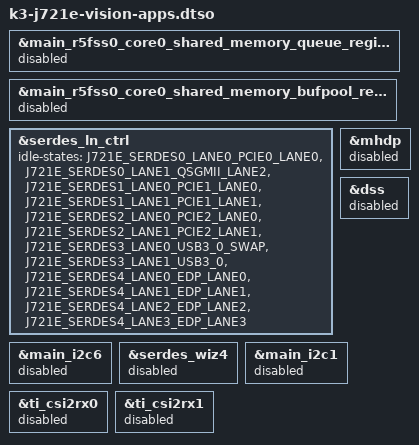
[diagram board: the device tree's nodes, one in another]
// SPDX-License-Identifier: GPL-2.0
/*
 * vision-apps: device-tree overlay
 *
 * Copyright (C) 2019 - 2021 Texas Instruments Incorporated - http://www.ti.com/
 */

/dts-v1/;
/plugin/;

#include <dt-bindings/mux/ti-serdes.h>

&main_r5fss0_core0_shared_memory_queue_region {
	status = "disabled";
};

&main_r5fss0_core0_shared_memory_bufpool_region {
	status = "disabled";
};

&serdes_ln_ctrl {
	idle-states = <J721E_SERDES0_LANE0_PCIE0_LANE0>, <J721E_SERDES0_LANE1_QSGMII_LANE2>,
		      <J721E_SERDES1_LANE0_PCIE1_LANE0>, <J721E_SERDES1_LANE1_PCIE1_LANE1>,
		      <J721E_SERDES2_LANE0_PCIE2_LANE0>, <J721E_SERDES2_LANE1_PCIE2_LANE1>,
		      <J721E_SERDES3_LANE0_USB3_0_SWAP>, <J721E_SERDES3_LANE1_USB3_0>,
		      <J721E_SERDES4_LANE0_EDP_LANE0>, <J721E_SERDES4_LANE1_EDP_LANE1>,
		      <J721E_SERDES4_LANE2_EDP_LANE2>, <J721E_SERDES4_LANE3_EDP_LANE3>;
};

#include "k3-j721e-rtos-memory-map.dtsi"

&main_i2c6 {
	status = "disabled";
};

&serdes_wiz4 {
	status = "disabled";
};

&mhdp {
	status = "disabled";
};

&dss {
	status = "disabled";
};

&main_i2c1 {
	status = "disabled";
};

&ti_csi2rx0 {
	status = "disabled";
};

&ti_csi2rx1 {
	status = "disabled";
};
